# MEC1721N_B0_LJ register map
Vendor: Microchip Technology; Series: MEC172x; File version: 0
CPU: CM4 r1p0, little endian, MPU, FPU, 3 interrupt priority bits, 172 interrupts
Registers are 32-bit, read-write, reset 0x0 unless marked. A register's access mark holds for its fields unless they carry their own. Offsets are from the block's base; [hi:lo] are bit positions.

## PHOT — This block monitors the PROCHOT# signal and designed to detect single assertions and monitor cumulative PROCHOT active time.
Base 0x40003400
0x00 CUCNT — PROCHOT Cumulative Count Register
  [23:0] ACTIVE — This register contains the current filtered PROCHOT Active Counter value.
0x04 DC_CNT — PROCHOT Duty Cycle Count Register
  [23:0] CNT — The contents of the PROCHOT Cumulative Count Register is copied into this register when the PROCHOT Duty Cycle Period Register transitions from 1 to 0.
0x08 DC_PER — PROCHOT Duty Cycle Period Register
  [23:0] PER — This register defines the number of 100KHz periods required for a duty cycle measurement.
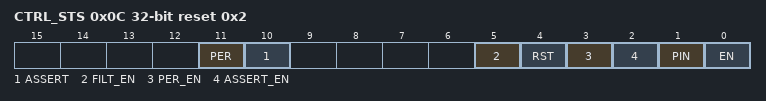
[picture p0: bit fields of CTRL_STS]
0x0C CTRL_STS reset 0x2 — PROCHOT Status/Control Register
  [11] PER — This sticky status bit is set to '1b' when the PROCHOT Period Counter transitions from '1b' to '0b.' (R/WC)
  [10] ASSERT — This bit is set when the PROCHOT Assertion Counter Register value is greater than or equal to the PROCHOT Assertion Counter Limit Register value. (R/WC)
  [5] FILT_EN — This bit determines whether a digital filter eliminates pulses on the PROCHOT# signal before PROCHOT# is sampled by the Assertion counter or the Active counter.
  [4] RST — Writing this self-clearing bit to one resets all the registers and logic in the PROCHOT Monitor block to its defined initial state.
  [3] PER_EN — This bit determines whether or not an interrupt will be generated when the PHOT_PERIOD bit is set.
  [2] ASSERT_EN — This bit determines whether or not an interrupt will be generated when the PHOT_ASSERT bit is set.
  [1] PIN — When PHOT_ENABLE is 1b, this bit reflects the state of the PROCHOT# Pin input.
  [0] EN — This bit enables the PROCHOT Monitor logic.
0x10 ASCNT — PROCHOT Assertion Counter Register
  [15:0] CNT — The PROCHOT Assertion Counter is a 16-bit up-counter that is clocked by the 100KHz and is gated and reset by the PROCHOT# input signal. This counter is used to measure a single PROCHOT assertion.
0x14 ASCLIM — PROCHOT Assertion Counter Register
  [15:0] CLIM — The PROCHOT Assertion Counter Limit register is compared to the 16-bit PROCHOT Assertion Counter.

## RC_ID0 — This interface provides a single pin interface which can discriminate a number of quantized RC constants.
Base 0x40001400; register names take the prefix RC_ID_
Same registers: RC_ID1 0x40001480, RC_ID2 0x40001500
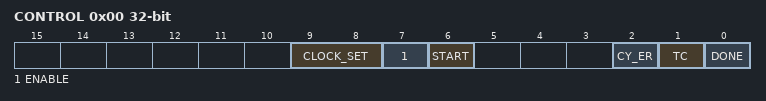
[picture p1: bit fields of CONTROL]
0x00 CONTROL — RC_ID Control Register
  [9:8] CLOCK_SET — This field selects the frequency of the Counter circuit clock. This field must retain the same value as long as the ENABLE bit in this register is 1.
  [7] ENABLE — Clearing the bit to 0 causes the RC_ID interface to enter the Reset state, gating its clocks, clearing the status bits in this register and entering into its lowest power state. Setting this bit to 1 causes the RC_ID interface to enter the Armed phase of an RC_ID measurement.
  [6] START — Setting this bit to 1 initiates the Discharged phase of an RC_ID measurement.
  [2] CY_ER — This bit is 1 if an RC_ID measurement encountered an error and the reading in the RC_ID Data Register is invalid. This bit is cleared to 0 when the RC_ID interface is in the Reset phase.
  [1] TC — This bit is cleared to 0 when the RC_ID interface is in the Reset phase, and set to 1 when the interface completes the Discharged phase of an RC_ID measurement.
  [0] DONE — This bit is cleared to 0 when the RC_ID interface is in the Reset phase, and set to 1 when the interface completes an RC_ID measurement.
0x04 DATA — Reads of this register provide the result of an RC_ID measurement.
  [15:0] RCID_DATA
